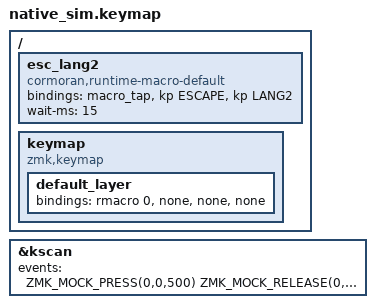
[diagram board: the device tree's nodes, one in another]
#include <behaviors.dtsi>
#include <behaviors/runtime_macro.dtsi>
#include <dt-bindings/zmk/keys.h>
#include <dt-bindings/zmk/kscan_mock.h>

// A default macro that was never saved is edited and then discarded before the first key (see
// src/test/macro_discard_test.c). Playing it must type what the devicetree says, not the edit.
/ {
    esc_lang2 {
        compatible = "cormoran,runtime-macro-default";
        bindings = <&macro_tap>, <&kp ESCAPE &kp LANG2>;
        wait-ms = <15>;
    };

    keymap {
        compatible = "zmk,keymap";
        default_layer {
            bindings = <&rmacro 0 &none &none &none>;
        };
    };
};

// The first delay is also waited before the first event, which leaves room for the edit and the
// discard.
&kscan {
    events = <
        ZMK_MOCK_PRESS(0,0,500)
        ZMK_MOCK_RELEASE(0,0,500)
    >;
};
